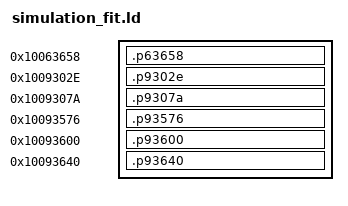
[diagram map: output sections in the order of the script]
SECTIONS {
    .p63658 0x10063658 : { *(.p63658) }
    .p9302e 0x1009302e : { *(.p9302e) }
    .p9307a 0x1009307a : { *(.p9307a) }
    .p93576 0x10093576 : { *(.p93576) }
    .p93600 0x10093600 : { *(.p93600) }
    .p93640 0x10093640 : { *(.p93640) }
}
character_records = 0x10093047;
other_records = 0x10093033;
four_cells = 0x10093087;
other_size = 0x1009307f;
add_hint = 0x10093489;
